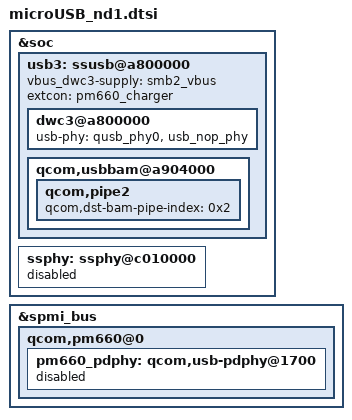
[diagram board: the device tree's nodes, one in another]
&soc {
	usb3: ssusb@a800000 {
		vbus_dwc3-supply = <&smb2_vbus>;
		extcon = <&pm660_charger>;
		dwc3@a800000 {
			usb-phy = <&qusb_phy0>, <&usb_nop_phy>;
		};
		qcom,usbbam@a904000 {
					qcom,pipe2 {
						qcom,dst-bam-pipe-index = <0x2>;
						};
					};
   
                };
        ssphy: ssphy@c010000 {
		status = "disabled";
               };
};
&spmi_bus { 
	qcom,pm660@0 {
		pm660_pdphy: qcom,usb-pdphy@1700 {
		status = "disabled";
		};
		};
};
